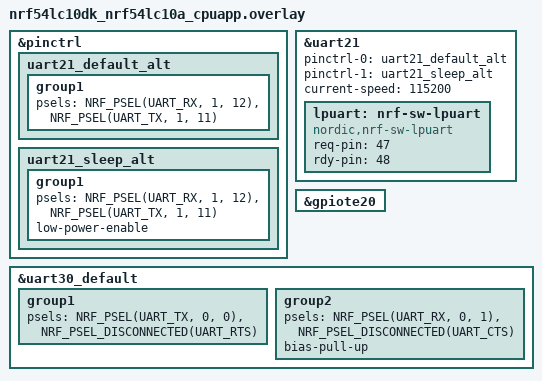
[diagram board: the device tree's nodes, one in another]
/* SPDX-License-Identifier: LicenseRef-Nordic-5-Clause */

/*
 * UART loopback: P1.11 <-> P1.12 (TX/RX on uart21).
 * SW LPUART handshake: req P1.15 (pin 47), rdy P1.16 (pin 48) — see sample README / CI fixture.
 */

&pinctrl {
	uart21_default_alt: uart21_default_alt {
		group1 {
			psels = <NRF_PSEL(UART_RX, 1, 12)>,
				<NRF_PSEL(UART_TX, 1, 11)>;
		};
	};

	uart21_sleep_alt: uart21_sleep_alt {
		group1 {
			psels = <NRF_PSEL(UART_RX, 1, 12)>,
				<NRF_PSEL(UART_TX, 1, 11)>;
			low-power-enable;
		};
	};
};

&uart21 {
	status = "okay";
	pinctrl-0 = <&uart21_default_alt>;
	pinctrl-1 = <&uart21_sleep_alt>;
	pinctrl-names = "default", "sleep";
	current-speed = <115200>;

	lpuart: nrf-sw-lpuart {
		compatible = "nordic,nrf-sw-lpuart";
		status = "okay";
		req-pin = <47>;
		rdy-pin = <48>;
	};
};

&gpiote20 {
	status = "okay";
};

&uart30_default {
	/* Disconnect CTS and RTS lines from pins.
	 * This is a workaround for increased current consumption
	 * (~250 uA more).
	 */
	group1 {
		psels = <NRF_PSEL(UART_TX, 0, 0)>,
			<NRF_PSEL_DISCONNECTED(UART_RTS)>;
	};

	group2 {
		psels = <NRF_PSEL(UART_RX, 0, 1)>,
			<NRF_PSEL_DISCONNECTED(UART_CTS)>;
		bias-pull-up;
	};
};
